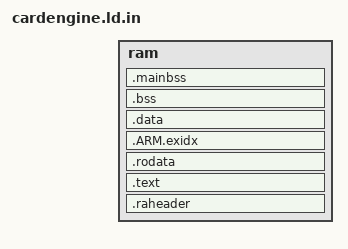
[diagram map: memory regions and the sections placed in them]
#include "ra_engine.h"

OUTPUT_FORMAT("elf32-littlearm", "elf32-bigarm", "elf32-littlearm")
OUTPUT_ARCH(arm)

MEMORY {
	ram	: ORIGIN = RA_REGION + RA_ENGINE_OFFSET, LENGTH = RA_ENGINE_MAX
}

__ra_stack_top = RA_REGION + RA_ENGINE_AREA;
/* No WRAM heap arena in the main-RAM variant */
__wram_heap_start = 0;
__wram_heap_end = 0;

SECTIONS
{
	/* struct RaEngineHeader must come first */
	.raheader : { KEEP (*(.raheader)) . = ALIGN(4); } >ram = 0xff

	.text : {
		*(.text*)
		*(.glue_7)
		*(.glue_7t)
		. = ALIGN(4);
	} >ram = 0xff

	.rodata : { *(.rodata) *(.rodata.*) . = ALIGN(4); } >ram = 0xff

	.ARM.exidx : { *(.ARM.exidx* .gnu.linkonce.armexidx.*) } >ram

	.data ALIGN(4) : {
		__data_start = ABSOLUTE(.);
		*(.data) *(.data.*)
		. = ALIGN(4);
		__data_end = ABSOLUTE(.);
	} >ram = 0xff

	/* Not in the binary: zeroed by raInit() */
	.bss ALIGN(4) (NOLOAD) : {
		__bss_start = ABSOLUTE(.);
		*(.bss*) *(COMMON)
		. = ALIGN(4);
		__bss_end = ABSOLUTE(.);
	} >ram

	.mainbss ALIGN(4) (NOLOAD) : {
		__mainbss_start = ABSOLUTE(.);
		*(.mainbss*)
		. = ALIGN(4);
		__mainbss_end = ABSOLUTE(.);
	} >ram

	/DISCARD/ : { *(.comment) *(.ARM.attributes) *(.note*) }
}
